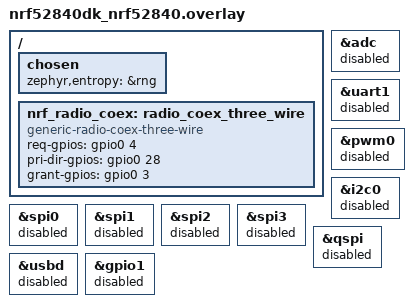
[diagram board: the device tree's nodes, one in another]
/* Copyright (c) 2020 Nordic Semiconductor ASA
 *
 * SPDX-License-Identifier: LicenseRef-Nordic-5-Clause
 */

/ {
	/*
	* In some default configurations within the nRF Connect SDK,
	* e.g. on nRF52840, the chosen zephyr,entropy node is &cryptocell.
	* This devicetree overlay ensures that default is overridden wherever it
	* is set, as this application uses the RNG node for entropy exclusively.
	*/
	chosen {
		zephyr,entropy = &rng;
	};
    nrf_radio_coex: radio_coex_three_wire {
		status = "okay";
		compatible = "generic-radio-coex-three-wire";
		req-gpios =     <&gpio0 4 (GPIO_ACTIVE_HIGH)>;
		pri-dir-gpios = <&gpio0 28 (GPIO_ACTIVE_HIGH)>;
		grant-gpios =   <&gpio0 3 (GPIO_ACTIVE_HIGH | GPIO_PULL_UP)>;
	};
};
&adc {
	status = "disabled";
};
&uart1 {
	status = "disabled";
};
&pwm0 {
	status = "disabled";
};
&i2c0 {
	status = "disabled";
};
&spi0 {
	status = "disabled";
};
&spi1 {
	status = "disabled";
};
&spi2 {
	status = "disabled";
};
&spi3 {
	status = "disabled";
};
&qspi {
	status = "disabled";
};
&usbd {
	status = "disabled";
};
&gpio1 {
	status = "disabled";
};
